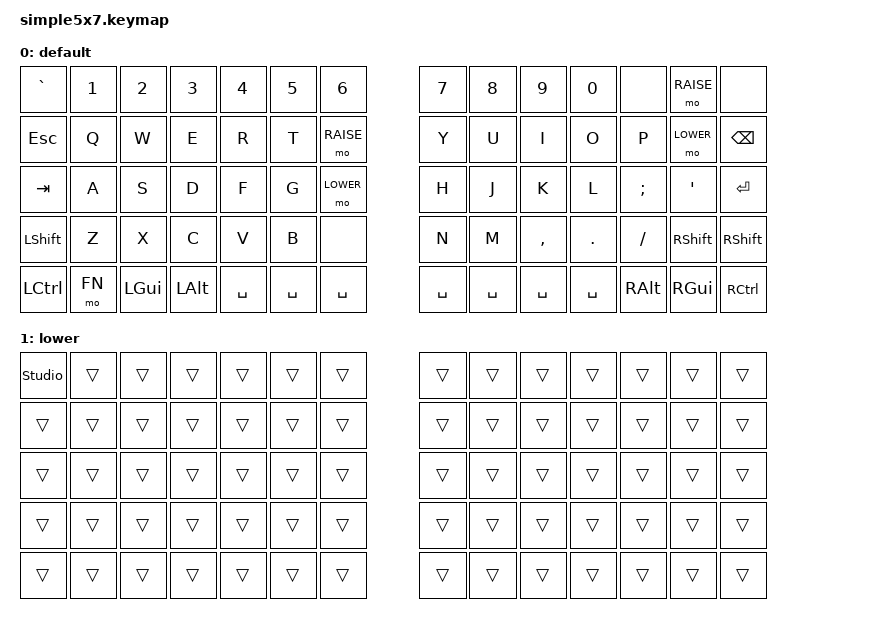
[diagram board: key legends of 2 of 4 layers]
#include <behaviors.dtsi>
#include <dt-bindings/zmk/keys.h>
#include <dt-bindings/zmk/bt.h>
#include <dt-bindings/zmk/ext_power.h>

#define BASE 0
#define LOWER 1
#define RAISE 2
#define ADJUST 3
#define FN 1

/ {

   // Activate ADJUST layer by pressing raise and lower
    conditional_layers {
        compatible = "zmk,conditional-layers";
        adjust_layer {
            if-layers = <LOWER RAISE>;
            then-layer = <ADJUST>;
        };
    };

    keymap {
        compatible = "zmk,keymap";

        default_layer {
            display-name = "default";
// ------------------------------------------------------------------------------------------------------------
// |   `   |  1  |  2  |  3   |  4   |  5   |       |         |   6   |  7    |  8    |  9   |   0   |       |       |
// |  ESC  |  Q  |  W  |  E   |  R   |  T   | RAISE |         |   Y   |  U    |  I    |  O   |   P   | BKSPC |       |
// |  TAB  |  A  |  S  |  D   |  F   |  G   | LOWER |         |   H   |  J    |  K    |  L   |   ;   |   '   |       |
// | SHIFT |  Z  |  X  |  C   |  V   |  B   |       |         |   N   |  M    |  ,    |  .   |   /   | SHIFT |       |
//               | GUI | ALT  | CTRL | LOWER| SPACE |         | SPACE |SPACE | SPACE | SPACE |  ALT  | GUI   | CTRL  |
            bindings = <

&kp GRAVE   &kp N1    &kp N2   &kp N3   &kp N4    &kp N5    &kp N6                  &kp N7    &kp N8    &kp N9    &kp N0    &none     &mo RAISE  &none      
&kp ESC     &kp Q     &kp W    &kp E    &kp R     &kp T     &mo RAISE               &kp Y     &kp U     &kp I     &kp O     &kp P     &mo LOWER  &kp BSPC   
&kp TAB     &kp A     &kp S    &kp D    &kp F     &kp G     &mo LOWER               &kp H     &kp J     &kp K     &kp L     &kp SEMI  &kp SQT    &kp RET   
&kp LSHFT   &kp Z     &kp X    &kp C    &kp V     &kp B     &none                   &kp N     &kp M     &kp COMMA &kp DOT   &kp FSLH  &kp RSHFT  &kp RSHFT
&kp LCTRL   &mo FN    &kp LGUI &kp LALT &kp SPACE &kp SPACE &kp SPACE               &kp SPACE &kp SPACE &kp SPACE &kp SPACE &kp RALT  &kp RGUI   &kp RCTRL
            
            >;
            sensor-bindings = <&inc_dec_kp C_VOL_UP C_VOL_DN &inc_dec_kp PG_UP PG_DN>;
        };

        lower_layer {
            display-name = "lower";
// TODO: Some binds are waiting for shifted keycode support.
// ------------------------------------------------------------------------------------------------------------
// |       |  F1 |  F2 |  F3  |  F4  |  F5  |     |             |  F6  |  F7   |  F8   |  F9  |  F10  |  F11  |  F12  |
// |   `   |  1  |  2  |  3   |  4   |  5   |     |             |  6   |  7    |  8    |  9   |   0   |   
// |       |  !  |  @  |  #   |  $   |  %   |     |             |  ^   |  &    |  *    |  (   |   )   |   |   |
// |       |  =  |  -  |  +   |  {   |  }   |     |             |  [   |  ]    |  ;    |  :   |   \   |       |
// |       |     |     |      |      |      |     |             |      |       |       |      |       |       |
            bindings = <
&studio_unlock  &trans  &trans  &trans  &trans  &trans  &trans          &trans  &trans  &trans  &trans  &trans  &trans      &trans 
&trans          &trans  &trans  &trans  &trans  &trans  &trans          &trans  &trans  &trans  &trans  &trans  &trans      &trans 
&trans          &trans  &trans  &trans  &trans  &trans  &trans          &trans  &trans  &trans  &trans  &trans  &trans      &trans 
&trans          &trans  &trans  &trans  &trans  &trans  &trans          &trans  &trans  &trans  &trans  &trans  &trans      &trans 
&trans          &trans  &trans  &trans  &trans  &trans  &trans          &trans  &trans  &trans  &trans  &trans  &trans      &trans 
            >;

            sensor-bindings = <&inc_dec_kp C_VOL_UP C_VOL_DN &inc_dec_kp PG_UP PG_DN>;
        };

        raise_layer {
            display-name = "raise";
// ------------------------------------------------------------------------------------------------------------
// | BTCLR | BT1  | BT2  |  BT3  |  BT4  |  BT5 |                |      |      |       |      |       |       |
// |       | INS  | PSCR | GUI   |       |      |                | PGUP |      |   ^   |      |       |       |
// |       | ALT  | CTRL | SHIFT |       | CAPS |                | PGDN |   <- |   v   |  ->  |  DEL  | BKSPC |
// |       | UNDO | CUT  | COPY  | PASTE |      |                |      |      |       |      |       |       |
//                |      |       |       |      |                |      |      |       |      |
            bindings = <
&bt BT_CLR      &bt BT_SEL 0 &bt BT_SEL 1 &bt BT_SEL 2 &bt BT_SEL 3 &bt BT_SEL 4    &trans  &trans  &trans  &trans  &trans  &trans      &trans
&trans          &trans  &trans  &trans  &trans  &trans  &trans                      &trans  &trans  &trans  &trans  &trans  &trans      &trans 
&trans          &trans  &trans  &trans  &trans  &trans  &trans                      &trans  &trans  &trans  &trans  &trans  &trans      &trans 
&trans          &trans  &trans  &trans  &trans  &trans  &trans                      &trans  &trans  &trans  &trans  &trans  &trans      &trans 
&trans          &trans  &trans  &trans  &trans  &trans  &trans                      &trans  &trans  &trans  &trans  &trans  &trans      &trans 
            >;

            sensor-bindings = <&inc_dec_kp C_VOL_UP C_VOL_DN &inc_dec_kp PG_UP PG_DN>;
        };

        adjust_layer {
// ----------------------------------------------------------------------------------------------------------------------------
// | BTCLR  |  BT1    |  BT2    |   BT3   |   BT4   |   BT5   |                  |      |      |       |      |       |       |
// | EXTPWR | RGB_HUD | RGB_HUI | RGB_SAD | RGB_SAI | RGB_EFF |                  |      |      |       |      |       |       |
// |        | RGB_BRD | RGB_BRI |         |         |         |                  |      |      |       |      |       |       |
// |        |         |         |         |         |         | RGB_TOG | |      |      |      |       |      |       |       |
//                    |         |         |         |         |         | |      |      |      |       |      |
            display-name = "adjust";
            bindings = <
&bt BT_CLR      &bt BT_SEL 0 &bt BT_SEL 1 &bt BT_SEL 2 &bt BT_SEL 3 &bt BT_SEL 4    &trans  &trans  &trans  &trans  &trans  &trans      &trans
&trans          &trans  &trans  &trans  &trans  &trans  &trans                      &trans  &trans  &trans  &trans  &trans  &trans      &trans 
&trans          &trans  &trans  &trans  &trans  &trans  &trans                      &trans  &trans  &trans  &trans  &trans  &studio_unlock &trans 
&trans          &trans  &trans  &trans  &trans  &trans  &trans                      &trans  &trans  &trans  &trans  &trans  &trans      &trans 
&trans          &trans  &trans  &trans  &trans  &trans  &trans                      &trans  &trans  &trans  &trans  &trans  &trans      &trans
            >;
            sensor-bindings = <
                &inc_dec_kp C_VOL_UP C_VOL_DN &inc_dec_kp PG_UP PG_DN
            >;
        };
    };
};
